AUTOSAR XML (schema 4-2-1)
package /RootP_ASWC_A7C
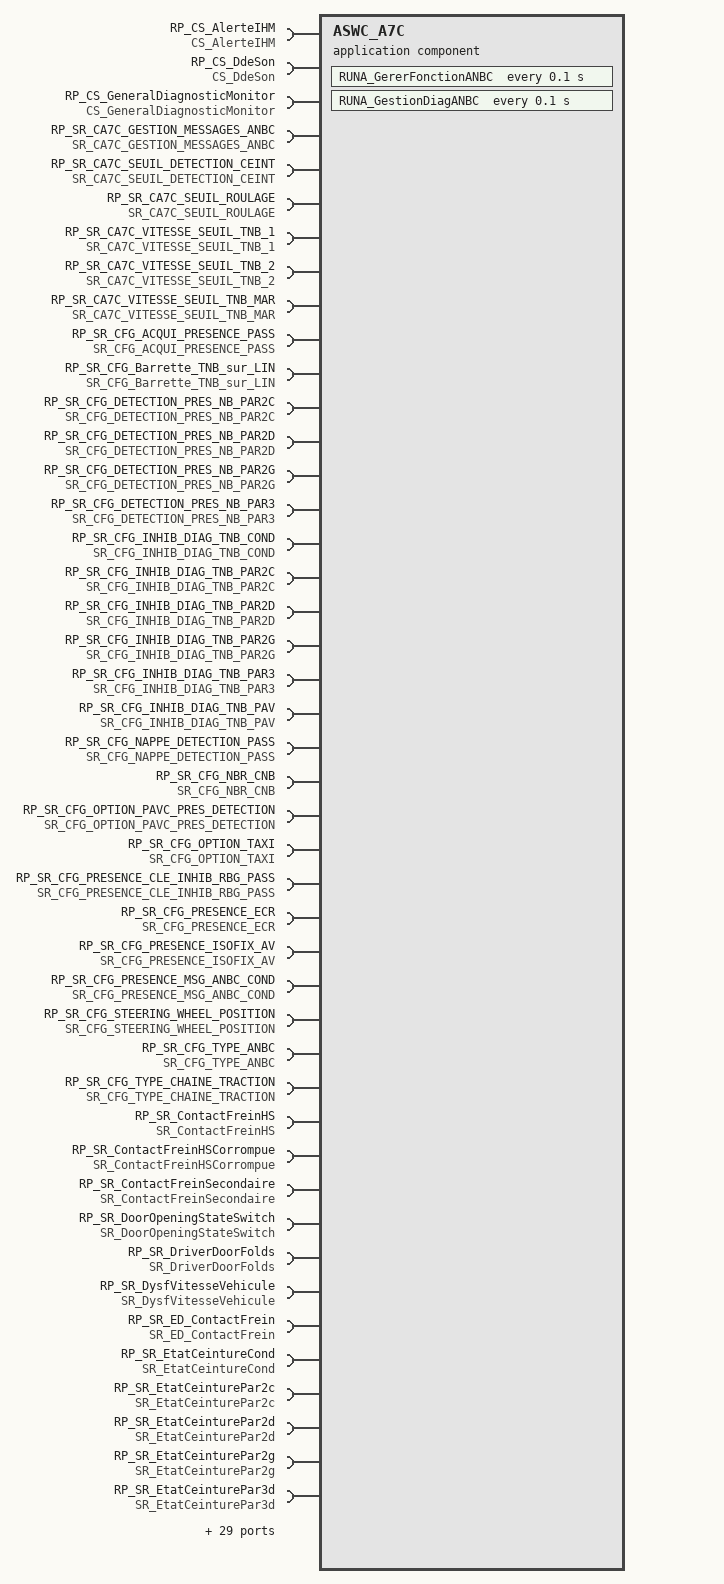
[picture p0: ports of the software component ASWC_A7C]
  application sw component type ASWC_A7C
    32 x provide/require port:
      PRP_SR_BMFPresente: nonqueued-receiver-com-spec{data-element=BMFPresente, enable-update=0, handle-data-status=1, handle-never-received=0, init-value=CONST_tLOG_0:0}, provided-required-interface=SR_BMFPresente
      PRP_SR_DdeClignoTemCeintAR2D: nonqueued-receiver-com-spec{data-element=DdeClignoTemCeintAR2D, enable-update=0, handle-data-status=1, handle-never-received=0, init-value=CONST_tLOG_0:0}, provided-required-interface=SR_DdeClignoTemCeintAR2D
      PRP_SR_DdeClignoTemCeintAR2G: nonqueued-receiver-com-spec{data-element=DdeClignoTemCeintAR2G, enable-update=0, handle-data-status=1, handle-never-received=0, init-value=CONST_tLOG_0:0}, provided-required-interface=SR_DdeClignoTemCeintAR2G
      PRP_SR_DdeClignoTemCeintAR2M: nonqueued-receiver-com-spec{data-element=DdeClignoTemCeintAR2M, enable-update=0, handle-data-status=1, handle-never-received=0, init-value=CONST_tLOG_0:0}, provided-required-interface=SR_DdeClignoTemCeintAR2M
      PRP_SR_DdeClignoTemCeintAR3D: nonqueued-receiver-com-spec{data-element=DdeClignoTemCeintAR3D, enable-update=0, handle-data-status=1, handle-never-received=0, init-value=CONST_tLOG_0:0}, provided-required-interface=SR_DdeClignoTemCeintAR3D
      PRP_SR_DdeClignoTemCeintAR3G: nonqueued-receiver-com-spec{data-element=DdeClignoTemCeintAR3G, enable-update=0, handle-data-status=1, handle-never-received=0, init-value=CONST_tLOG_0:0}, provided-required-interface=SR_DdeClignoTemCeintAR3G
      PRP_SR_DdeClignoTemCeintCond: nonqueued-receiver-com-spec{data-element=DdeClignoTemCeintCond, enable-update=0, handle-data-status=1, handle-never-received=0, init-value=CONST_tLOG_0:0}, provided-required-interface=SR_DdeClignoTemCeintCond
      PRP_SR_DdeClignoTemCeintPav: nonqueued-receiver-com-spec{data-element=DdeClignoTemCeintPav, enable-update=0, handle-data-status=1, handle-never-received=0, init-value=CONST_tLOG_0:0}, provided-required-interface=SR_DdeClignoTemCeintPav
      PRP_SR_DdeClignoTemCeintPavC: nonqueued-receiver-com-spec{data-element=DdeClignoTemCeintPavC, enable-update=0, handle-data-status=1, handle-never-received=0, init-value=CONST_tLOG_0:0}, provided-required-interface=SR_DdeClignoTemCeintPavC
      PRP_SR_DdeTemoinCeintureAR2D: nonqueued-receiver-com-spec{data-element=DdeTemoinCeintureAR2D, enable-update=0, handle-data-status=1, handle-never-received=0, init-value=CONST_tLOG_0:0}, provided-required-interface=SR_DdeTemoinCeintureAR2D
      PRP_SR_DdeTemoinCeintureAR2G: nonqueued-receiver-com-spec{data-element=DdeTemoinCeintureAR2G, enable-update=0, handle-data-status=1, handle-never-received=0, init-value=CONST_tLOG_0:0}, provided-required-interface=SR_DdeTemoinCeintureAR2G
      PRP_SR_DdeTemoinCeintureAR2M: nonqueued-receiver-com-spec{data-element=DdeTemoinCeintureAR2M, enable-update=0, handle-data-status=1, handle-never-received=0, init-value=CONST_tLOG_0:0}, provided-required-interface=SR_DdeTemoinCeintureAR2M
      PRP_SR_DdeTemoinCeintureAR3D: nonqueued-receiver-com-spec{data-element=DdeTemoinCeintureAR3D, enable-update=0, handle-data-status=1, handle-never-received=0, init-value=CONST_tLOG_0:0}, provided-required-interface=SR_DdeTemoinCeintureAR3D
      PRP_SR_DdeTemoinCeintureAR3G: nonqueued-receiver-com-spec{data-element=DdeTemoinCeintureAR3G, enable-update=0, handle-data-status=1, handle-never-received=0, init-value=CONST_tLOG_0:0}, provided-required-interface=SR_DdeTemoinCeintureAR3G
      PRP_SR_DdeTemoinCeintureCond: nonqueued-receiver-com-spec{data-element=DdeTemoinCeintureCond, enable-update=0, handle-data-status=1, handle-never-received=0, init-value=CONST_tLOG_0:0}, provided-required-interface=SR_DdeTemoinCeintureCond
      PRP_SR_DdeTemoinCeinturePav: nonqueued-receiver-com-spec{data-element=DdeTemoinCeinturePav, enable-update=0, handle-data-status=1, handle-never-received=0, init-value=CONST_tLOG_0:0}, provided-required-interface=SR_DdeTemoinCeinturePav
      PRP_SR_DdeTemoinCeinturePavC: nonqueued-receiver-com-spec{data-element=DdeTemoinCeinturePavC, enable-update=0, handle-data-status=1, handle-never-received=0, init-value=CONST_tLOG_0:0}, provided-required-interface=SR_DdeTemoinCeinturePavC
      PRP_SR_DiagDefautPresenceConducteur: nonqueued-receiver-com-spec{data-element=DiagDefautPresenceConducteur, enable-update=0, handle-data-status=1, handle-never-received=0, init-value=CONST_DiagDefautPresenceConducteur_t_cDefautPresConducteur_cDefautPresConducteur_Ok:0}, provided-required-interface=SR_DiagDefautPresenceConducteur
      PRP_SR_EtatBouclageDiff: nonqueued-receiver-com-spec{data-element=EtatBouclageDiff, enable-update=0, handle-data-status=1, handle-never-received=0, init-value=CONST_t_cBouclage_0:0}, provided-required-interface=SR_EtatBouclageDiff
      PRP_SR_PresenceConducteurDiag: nonqueued-receiver-com-spec{data-element=PresenceConducteurDiag, enable-update=0, handle-data-status=1, handle-never-received=0, init-value=CONST_tLOG_0:0}, provided-required-interface=SR_PresenceConducteurDiag
      PRP_SR_PresenceConducteurMux: nonqueued-receiver-com-spec{data-element=PresenceConducteurMux, enable-update=0, handle-data-status=1, handle-never-received=0, init-value=CONST_PresenceConducteurMux_t_cPresenceConducteur_cPresenceConducteur_Absent:1}, provided-required-interface=SR_PresenceConducteurMux
      PRP_SR_PresenceSimpleConducteur: nonqueued-receiver-com-spec{data-element=PresenceSimpleConducteur, enable-update=0, handle-data-status=1, handle-never-received=0, init-value=CONST_PresenceSimpleConducteur_t_cPresenceSimpleConducteur_cPresenceSimpleConducteur_Absent:0}, provided-required-interface=SR_PresenceSimpleConducteur
      PRP_SR_SAV_EtatCNBMemorisePar2c: nonqueued-receiver-com-spec{data-element=SAV_EtatCNBMemorisePar2c, enable-update=0, handle-data-status=1, handle-never-received=0, init-value=CONST_tLOG_0:0}, provided-required-interface=SR_SAV_EtatCNBMemorisePar2c
      PRP_SR_SAV_EtatCNBMemorisePar2d: nonqueued-receiver-com-spec{data-element=SAV_EtatCNBMemorisePar2d, enable-update=0, handle-data-status=1, handle-never-received=0, init-value=CONST_tLOG_0:0}, provided-required-interface=SR_SAV_EtatCNBMemorisePar2d
      PRP_SR_SAV_EtatCNBMemorisePar2g: nonqueued-receiver-com-spec{data-element=SAV_EtatCNBMemorisePar2g, enable-update=0, handle-data-status=1, handle-never-received=0, init-value=CONST_tLOG_0:0}, provided-required-interface=SR_SAV_EtatCNBMemorisePar2g
      PRP_SR_SAV_EtatCNBMemorisePar3d: nonqueued-receiver-com-spec{data-element=SAV_EtatCNBMemorisePar3d, enable-update=0, handle-data-status=1, handle-never-received=0, init-value=CONST_tLOG_0:0}, provided-required-interface=SR_SAV_EtatCNBMemorisePar3d
      PRP_SR_SAV_EtatCNBMemorisePar3g: nonqueued-receiver-com-spec{data-element=SAV_EtatCNBMemorisePar3g, enable-update=0, handle-data-status=1, handle-never-received=0, init-value=CONST_tLOG_0:0}, provided-required-interface=SR_SAV_EtatCNBMemorisePar3g
      PRP_SR_SAV_EtatCNBMemorisePavC: nonqueued-receiver-com-spec{data-element=SAV_EtatCNBMemorisePavC, enable-update=0, handle-data-status=1, handle-never-received=0, init-value=CONST_tLOG_0:0}, provided-required-interface=SR_SAV_EtatCNBMemorisePavC
      PRP_SR_SAV_EtatCNBMemorisePavd: nonqueued-receiver-com-spec{data-element=SAV_EtatCNBMemorisePavd, enable-update=0, handle-data-status=1, handle-never-received=0, init-value=CONST_tLOG_0:0}, provided-required-interface=SR_SAV_EtatCNBMemorisePavd
      PRP_SR_SAV_EtatCNBMemorisePavg: nonqueued-receiver-com-spec{data-element=SAV_EtatCNBMemorisePavg, enable-update=0, handle-data-status=1, handle-never-received=0, init-value=CONST_tLOG_0:0}, provided-required-interface=SR_SAV_EtatCNBMemorisePavg
      PRP_SR_SAV_EtatPresenceMemorisePav: nonqueued-receiver-com-spec{data-element=SAV_EtatPresenceMemorisePav, enable-update=0, handle-data-status=1, handle-never-received=0, init-value=CONST_tLOG_0:0}, provided-required-interface=SR_SAV_EtatPresenceMemorisePav
      PRP_SR_TypeSonANBC: nonqueued-receiver-com-spec{data-element=TypeSonANBC, enable-update=0, handle-data-status=1, handle-never-received=0, init-value=CONST_t_cTypeSonANBC_0:0}, provided-required-interface=SR_TypeSonANBC
    73 x require port:
      RP_CS_AlerteIHM: required-interface=CS_AlerteIHM
      RP_CS_DdeSon: required-interface=CS_DdeSon
      RP_CS_GeneralDiagnosticMonitor: required-interface=CS_GeneralDiagnosticMonitor
      RP_SR_CA7C_GESTION_MESSAGES_ANBC: nonqueued-receiver-com-spec{data-element=CA7C_GESTION_MESSAGES_ANBC, enable-update=0, handle-data-status=1, handle-never-received=0, init-value=CONST_tLOG_1:1}, required-interface=SR_CA7C_GESTION_MESSAGES_ANBC
      RP_SR_CA7C_SEUIL_DETECTION_CEINT: nonqueued-receiver-com-spec{data-element=CA7C_SEUIL_DETECTION_CEINT, enable-update=0, handle-data-status=1, handle-never-received=0, init-value=CONST_tBYTE_20:20}, required-interface=SR_CA7C_SEUIL_DETECTION_CEINT
      RP_SR_CA7C_SEUIL_ROULAGE: nonqueued-receiver-com-spec{data-element=CA7C_SEUIL_ROULAGE, enable-update=0, handle-data-status=1, handle-never-received=0, init-value=CONST_tBYTE_3:3}, required-interface=SR_CA7C_SEUIL_ROULAGE
      RP_SR_CA7C_VITESSE_SEUIL_TNB_1: nonqueued-receiver-com-spec{data-element=CA7C_VITESSE_SEUIL_TNB_1, enable-update=0, handle-data-status=1, handle-never-received=0, init-value=CONST_tBYTE_20:20}, required-interface=SR_CA7C_VITESSE_SEUIL_TNB_1
      RP_SR_CA7C_VITESSE_SEUIL_TNB_2: nonqueued-receiver-com-spec{data-element=CA7C_VITESSE_SEUIL_TNB_2, enable-update=0, handle-data-status=1, handle-never-received=0, init-value=CONST_tBYTE_20:20}, required-interface=SR_CA7C_VITESSE_SEUIL_TNB_2
      RP_SR_CA7C_VITESSE_SEUIL_TNB_MAR: nonqueued-receiver-com-spec{data-element=CA7C_VITESSE_SEUIL_TNB_MAR, enable-update=0, handle-data-status=1, handle-never-received=0, init-value=CONST_tBYTE_10:10}, required-interface=SR_CA7C_VITESSE_SEUIL_TNB_MAR
      RP_SR_CFG_ACQUI_PRESENCE_PASS: nonqueued-receiver-com-spec{data-element=CFG_ACQUI_PRESENCE_PASS, enable-update=0, handle-data-status=1, handle-never-received=0, init-value=CONST_tLOG_0:0}, required-interface=SR_CFG_ACQUI_PRESENCE_PASS
      RP_SR_CFG_Barrette_TNB_sur_LIN: nonqueued-receiver-com-spec{data-element=CFG_Barrette_TNB_sur_LIN, enable-update=0, handle-data-status=1, handle-never-received=0, init-value=CONST_tLOG_0:0}, required-interface=SR_CFG_Barrette_TNB_sur_LIN
      RP_SR_CFG_DETECTION_PRES_NB_PAR2C: nonqueued-receiver-com-spec{data-element=CFG_DETECTION_PRES_NB_PAR2C, enable-update=0, handle-data-status=1, handle-never-received=0, init-value=CONST_tLOG_0:0}, required-interface=SR_CFG_DETECTION_PRES_NB_PAR2C
      RP_SR_CFG_DETECTION_PRES_NB_PAR2D: nonqueued-receiver-com-spec{data-element=CFG_DETECTION_PRES_NB_PAR2D, enable-update=0, handle-data-status=1, handle-never-received=0, init-value=CONST_tLOG_0:0}, required-interface=SR_CFG_DETECTION_PRES_NB_PAR2D
      RP_SR_CFG_DETECTION_PRES_NB_PAR2G: nonqueued-receiver-com-spec{data-element=CFG_DETECTION_PRES_NB_PAR2G, enable-update=0, handle-data-status=1, handle-never-received=0, init-value=CONST_tLOG_0:0}, required-interface=SR_CFG_DETECTION_PRES_NB_PAR2G
      RP_SR_CFG_DETECTION_PRES_NB_PAR3: nonqueued-receiver-com-spec{data-element=CFG_DETECTION_PRES_NB_PAR3, enable-update=0, handle-data-status=1, handle-never-received=0, init-value=CONST_tLOG_0:0}, required-interface=SR_CFG_DETECTION_PRES_NB_PAR3
      RP_SR_CFG_INHIB_DIAG_TNB_COND: nonqueued-receiver-com-spec{data-element=CFG_INHIB_DIAG_TNB_COND, enable-update=0, handle-data-status=1, handle-never-received=0, init-value=CONST_tLOG_0:0}, required-interface=SR_CFG_INHIB_DIAG_TNB_COND
      RP_SR_CFG_INHIB_DIAG_TNB_PAR2C: nonqueued-receiver-com-spec{data-element=CFG_INHIB_DIAG_TNB_PAR2C, enable-update=0, handle-data-status=1, handle-never-received=0, init-value=CONST_tLOG_0:0}, required-interface=SR_CFG_INHIB_DIAG_TNB_PAR2C
      RP_SR_CFG_INHIB_DIAG_TNB_PAR2D: nonqueued-receiver-com-spec{data-element=CFG_INHIB_DIAG_TNB_PAR2D, enable-update=0, handle-data-status=1, handle-never-received=0, init-value=CONST_tLOG_0:0}, required-interface=SR_CFG_INHIB_DIAG_TNB_PAR2D
      RP_SR_CFG_INHIB_DIAG_TNB_PAR2G: nonqueued-receiver-com-spec{data-element=CFG_INHIB_DIAG_TNB_PAR2G, enable-update=0, handle-data-status=1, handle-never-received=0, init-value=CONST_tLOG_0:0}, required-interface=SR_CFG_INHIB_DIAG_TNB_PAR2G
      RP_SR_CFG_INHIB_DIAG_TNB_PAR3: nonqueued-receiver-com-spec{data-element=CFG_INHIB_DIAG_TNB_PAR3, enable-update=0, handle-data-status=1, handle-never-received=0, init-value=CONST_tLOG_0:0}, required-interface=SR_CFG_INHIB_DIAG_TNB_PAR3
      RP_SR_CFG_INHIB_DIAG_TNB_PAV: nonqueued-receiver-com-spec{data-element=CFG_INHIB_DIAG_TNB_PAV, enable-update=0, handle-data-status=1, handle-never-received=0, init-value=CONST_tLOG_0:0}, required-interface=SR_CFG_INHIB_DIAG_TNB_PAV
      RP_SR_CFG_NAPPE_DETECTION_PASS: nonqueued-receiver-com-spec{data-element=CFG_NAPPE_DETECTION_PASS, enable-update=0, handle-data-status=1, handle-never-received=0, init-value=CONST_tLOG_0:0}, required-interface=SR_CFG_NAPPE_DETECTION_PASS
      RP_SR_CFG_NBR_CNB: nonqueued-receiver-com-spec{data-element=CFG_NBR_CNB, enable-update=0, handle-data-status=1, handle-never-received=0, init-value=CONST_t_CFG_NBR_CNB_0:0}, required-interface=SR_CFG_NBR_CNB
      RP_SR_CFG_OPTION_PAVC_PRES_DETECTION: nonqueued-receiver-com-spec{data-element=CFG_OPTION_PAVC_PRES_DETECTION, enable-update=0, handle-data-status=1, handle-never-received=0, init-value=CONST_tLOG_0:0}, required-interface=SR_CFG_OPTION_PAVC_PRES_DETECTION
      RP_SR_CFG_OPTION_TAXI: nonqueued-receiver-com-spec{data-element=CFG_OPTION_TAXI, enable-update=0, handle-data-status=1, handle-never-received=0, init-value=CONST_tLOG_0:0}, required-interface=SR_CFG_OPTION_TAXI
      RP_SR_CFG_PRESENCE_CLE_INHIB_RBG_PASS: nonqueued-receiver-com-spec{data-element=CFG_PRESENCE_CLE_INHIB_RBG_PASS, enable-update=0, handle-data-status=1, handle-never-received=0, init-value=CONST_tLOG_0:0}, required-interface=SR_CFG_PRESENCE_CLE_INHIB_RBG_PASS
      RP_SR_CFG_PRESENCE_ECR: nonqueued-receiver-com-spec{data-element=CFG_PRESENCE_ECR, enable-update=0, handle-data-status=1, handle-never-received=0, init-value=CONST_t_cECR_A_0:0}, required-interface=SR_CFG_PRESENCE_ECR
      RP_SR_CFG_PRESENCE_ISOFIX_AV: nonqueued-receiver-com-spec{data-element=CFG_PRESENCE_ISOFIX_AV, enable-update=0, handle-data-status=1, handle-never-received=0, init-value=CONST_tLOG_0:0}, required-interface=SR_CFG_PRESENCE_ISOFIX_AV
      RP_SR_CFG_PRESENCE_MSG_ANBC_COND: nonqueued-receiver-com-spec{data-element=CFG_PRESENCE_MSG_ANBC_COND, enable-update=0, handle-data-status=1, handle-never-received=0, init-value=CONST_tLOG_0:0}, required-interface=SR_CFG_PRESENCE_MSG_ANBC_COND
      RP_SR_CFG_STEERING_WHEEL_POSITION: nonqueued-receiver-com-spec{data-element=CFG_STEERING_WHEEL_POSITION, enable-update=0, handle-data-status=1, handle-never-received=0, init-value=CONST_CFG_STEERING_WHEEL_POSITION_t_SteeringWheelPosition_eSteeringWheelPosition_Invalid:0}, required-interface=SR_CFG_STEERING_WHEEL_POSITION
      RP_SR_CFG_TYPE_ANBC: nonqueued-receiver-com-spec{data-element=CFG_TYPE_ANBC, enable-update=0, handle-data-status=1, handle-never-received=0, init-value=CONST_tLOG_0:0}, required-interface=SR_CFG_TYPE_ANBC
      RP_SR_CFG_TYPE_CHAINE_TRACTION: nonqueued-receiver-com-spec{data-element=CFG_TYPE_CHAINE_TRACTION, enable-update=0, handle-data-status=1, handle-never-received=0, init-value=CONST_CFG_TYPE_CHAINE_TRACTION_t_cTCT_cTCT_MTH:0}, required-interface=SR_CFG_TYPE_CHAINE_TRACTION
      RP_SR_ContactFreinHS: nonqueued-receiver-com-spec{data-element=ContactFreinHS, enable-update=0, handle-data-status=1, handle-never-received=0, init-value=CONST_tLOG_0:0}, required-interface=SR_ContactFreinHS
      RP_SR_ContactFreinHSCorrompue: nonqueued-receiver-com-spec{data-element=ContactFreinHSCorrompue, enable-update=0, handle-data-status=1, handle-never-received=0, init-value=CONST_tLOG_0:0}, required-interface=SR_ContactFreinHSCorrompue
      RP_SR_ContactFreinSecondaire: nonqueued-receiver-com-spec{data-element=ContactFreinSecondaire, enable-update=0, handle-data-status=1, handle-never-received=0, init-value=CONST_t_cContactFrein_0:0}, required-interface=SR_ContactFreinSecondaire
      RP_SR_DoorOpeningStateSwitch: nonqueued-receiver-com-spec{data-element=DoorOpeningState, enable-update=0, handle-data-status=1, handle-never-received=0, init-value=CONST_DoorOpeningState_tOpeningPosition_eMVA_None:0}, required-interface=SR_DoorOpeningStateSwitch
      RP_SR_DriverDoorFolds: required-interface=SR_DriverDoorFolds
        required-com-specs:
          data-element=DriverOpeningStateFolds, enable-update=0, handle-data-status=1, handle-never-received=0, init-value=CONST_tLOG_0:0
          data-element=DriverOpeningStateFoldsStatus, enable-update=0, handle-data-status=1, handle-never-received=0, init-value=CONST_DriverOpeningStateFoldsStatus_t_DriverOpeningStateFoldsStatus_eMVA_NoDefect:0
      RP_SR_DysfVitesseVehicule: nonqueued-receiver-com-spec{data-element=DysfVitesseVehicule, enable-update=0, handle-data-status=1, handle-never-received=0, init-value=CONST_t_cVitv_0:0}, required-interface=SR_DysfVitesseVehicule
      RP_SR_ED_ContactFrein: nonqueued-receiver-com-spec{data-element=ED_ContactFrein, enable-update=0, handle-data-status=1, handle-never-received=0, init-value=CONST_tLOG_0:0}, required-interface=SR_ED_ContactFrein
      RP_SR_EtatCeintureCond: nonqueued-receiver-com-spec{data-element=EtatCeintureCond, enable-update=0, handle-data-status=1, handle-never-received=0, init-value=CONST_EtatCeintureCond_t_cTNB_cTNB_Invalide:3}, required-interface=SR_EtatCeintureCond
      RP_SR_EtatCeinturePar2c: nonqueued-receiver-com-spec{data-element=EtatCeinturePar2c, enable-update=0, handle-data-status=1, handle-never-received=0, init-value=CONST_EtatCeinturePar2c_t_cTNB_cTNB_Invalide:3}, required-interface=SR_EtatCeinturePar2c
      RP_SR_EtatCeinturePar2d: nonqueued-receiver-com-spec{data-element=EtatCeinturePar2d, enable-update=0, handle-data-status=1, handle-never-received=0, init-value=CONST_EtatCeinturePar2d_t_cTNB_cTNB_Invalide:3}, required-interface=SR_EtatCeinturePar2d
      RP_SR_EtatCeinturePar2g: nonqueued-receiver-com-spec{data-element=EtatCeinturePar2g, enable-update=0, handle-data-status=1, handle-never-received=0, init-value=CONST_EtatCeinturePar2g_t_cTNB_cTNB_Invalide:3}, required-interface=SR_EtatCeinturePar2g
      RP_SR_EtatCeinturePar3d: nonqueued-receiver-com-spec{data-element=EtatCeinturePar3d, enable-update=0, handle-data-status=1, handle-never-received=0, init-value=CONST_EtatCeinturePar3d_t_cTNB_cTNB_Invalide:3}, required-interface=SR_EtatCeinturePar3d
      RP_SR_EtatCeinturePar3g: nonqueued-receiver-com-spec{data-element=EtatCeinturePar3g, enable-update=0, handle-data-status=1, handle-never-received=0, init-value=CONST_EtatCeinturePar3g_t_cTNB_cTNB_Invalide:3}, required-interface=SR_EtatCeinturePar3g
      RP_SR_EtatCeinturePav: nonqueued-receiver-com-spec{data-element=EtatCeinturePav, enable-update=0, handle-data-status=1, handle-never-received=0, init-value=CONST_EtatCeinturePav_t_cTNB_cTNB_Invalide:3}, required-interface=SR_EtatCeinturePav
      RP_SR_EtatCeinturePavC: nonqueued-receiver-com-spec{data-element=EtatCeinturePavC, enable-update=0, handle-data-status=1, handle-never-received=0, init-value=CONST_EtatCeinturePavC_t_cTNB_cTNB_Invalide:3}, required-interface=SR_EtatCeinturePavC
      RP_SR_EtatClefInhibRBAGPassager: nonqueued-receiver-com-spec{data-element=EtatClefInhibRBAGPassager, enable-update=0, handle-data-status=1, handle-never-received=0, init-value=CONST_t_cInhibRBGPass_0:0}, required-interface=SR_EtatClefInhibRBAGPassager
      RP_SR_EtatGMP: nonqueued-receiver-com-spec{data-element=EtatGMP, enable-update=0, handle-data-status=1, handle-never-received=0, init-value=CONST_EtatGMP_t_GM_GMP_GM_GMPCoupe:1}, required-interface=SR_EtatGMP
      RP_SR_EtatPrincipalSEV: nonqueued-receiver-com-spec{data-element=EtatPrincipalSEV, enable-update=0, handle-data-status=1, handle-never-received=0, init-value=CONST_EtatPrincipalSEV_t_SEV_SEV_Arret:105}, required-interface=SR_EtatPrincipalSEV
      RP_SR_InfoCpoCondRepli: nonqueued-receiver-com-spec{data-element=InfoCpoCondRepli, enable-update=0, handle-data-status=1, handle-never-received=0, init-value=CONST_tLOG_0:0}, required-interface=SR_InfoCpoCondRepli
      RP_SR_InterMemoDefauts: nonqueued-receiver-com-spec{data-element=InterMemoDefauts, enable-update=0, handle-data-status=1, handle-never-received=0, init-value=CONST_tLOG_0:0}, required-interface=SR_InterMemoDefauts
      RP_SR_MarcheArriere: nonqueued-receiver-com-spec{data-element=MarcheArriere, enable-update=0, handle-data-status=1, handle-never-received=0, init-value=CONST_tLOG_0:0}, required-interface=SR_MarcheArriere
      RP_SR_PhaseVieLS: nonqueued-receiver-com-spec{data-element=PhaseVieLS, enable-update=0, handle-data-status=1, handle-never-received=0, init-value=CONST_t_cCANLS_0:0}, required-interface=SR_PhaseVieLS
      RP_SR_PresencePassagerAvant: nonqueued-receiver-com-spec{data-element=PresencePassagerAvant, enable-update=0, handle-data-status=1, handle-never-received=0, init-value=CONST_tLOG_0:0}, required-interface=SR_PresencePassagerAvant
      RP_SR_SAV_CondaRealisee: nonqueued-receiver-com-spec{data-element=SAV_CondaRealisee, enable-update=0, handle-data-status=1, handle-never-received=0, init-value=CONST_SAV_CondaRealisee_t_cCR_cCR_Decondamne:1}, required-interface=SR_SAV_CondaRealisee
      RP_SR_SAV_EtatOuvrants: nonqueued-receiver-com-spec{data-element=SAV_EtatOuvrants, enable-update=0, handle-data-status=1, handle-never-received=0, init-value=CONST_t_cmEO_0:0}, required-interface=SR_SAV_EtatOuvrants
      RP_SR_SEC_ConfigSEV: nonqueued-receiver-com-spec{data-element=SEC_ConfigSEV, enable-update=0, handle-data-status=1, handle-never-received=0, init-value=CONST_t_cCSEV_4:4}, required-interface=SR_SEC_ConfigSEV
      RP_SR_TA7C_BOUCLAGE_CEINT_COND: nonqueued-receiver-com-spec{data-element=TA7C_BOUCLAGE_CEINT_COND, enable-update=0, handle-data-status=1, handle-never-received=0, init-value=CONST_t_TA7C_BOUCLAGE_CEINT_COND_60:60}, required-interface=SR_TA7C_BOUCLAGE_CEINT_COND
      RP_SR_TA7C_CONFIRM_DEBOUCLAGE_CEINT: nonqueued-receiver-com-spec{data-element=TA7C_CONFIRM_DEBOUCLAGE_CEINT, enable-update=0, handle-data-status=1, handle-never-received=0, init-value=CONST_tBYTE_1:1}, required-interface=SR_TA7C_CONFIRM_DEBOUCLAGE_CEINT
      RP_SR_TA7C_CONFIRM_OUVERTURE_PORTE: nonqueued-receiver-com-spec{data-element=TA7C_CONFIRM_OUVERTURE_PORTE, enable-update=0, handle-data-status=1, handle-never-received=0, init-value=CONST_tBYTE_1:1}, required-interface=SR_TA7C_CONFIRM_OUVERTURE_PORTE
      RP_SR_TA7C_DUREE_FORCAGE_TEMOINS_ARR: nonqueued-receiver-com-spec{data-element=TA7C_DUREE_FORCAGE_TEMOINS_ARR, enable-update=0, handle-data-status=1, handle-never-received=0, init-value=CONST_tBYTE_30:30}, required-interface=SR_TA7C_DUREE_FORCAGE_TEMOINS_ARR
      RP_SR_TA7C_FORCAGE_MAX_TNB: nonqueued-receiver-com-spec{data-element=TA7C_FORCAGE_MAX_TNB, enable-update=0, handle-data-status=1, handle-never-received=0, init-value=CONST_tBYTE_30:30}, required-interface=SR_TA7C_FORCAGE_MAX_TNB
      RP_SR_T_DUREE_SON_ANBC_NIV1: nonqueued-receiver-com-spec{data-element=T_DUREE_SON_ANBC_NIV1, enable-update=0, handle-data-status=1, handle-never-received=0, init-value=CONST_tBYTE_15:15}, required-interface=SR_T_DUREE_SON_ANBC_NIV1
      RP_SR_T_DUREE_SON_ANBC_NIV1_PRIM: nonqueued-receiver-com-spec{data-element=T_DUREE_SON_ANBC_NIV1_PRIM, enable-update=0, handle-data-status=1, handle-never-received=0, init-value=CONST_tBYTE_0:0}, required-interface=SR_T_DUREE_SON_ANBC_NIV1_PRIM
      RP_SR_T_DUREE_SON_ANBC_NIV2: nonqueued-receiver-com-spec{data-element=T_DUREE_SON_ANBC_NIV2, enable-update=0, handle-data-status=1, handle-never-received=0, init-value=CONST_tBYTE_15:15}, required-interface=SR_T_DUREE_SON_ANBC_NIV2
      RP_SR_T_DUREE_SON_ANBC_NIV2_PRIM: nonqueued-receiver-com-spec{data-element=T_DUREE_SON_ANBC_NIV2_PRIM, enable-update=0, handle-data-status=1, handle-never-received=0, init-value=CONST_tBYTE_0:0}, required-interface=SR_T_DUREE_SON_ANBC_NIV2_PRIM
      RP_SR_T_DUREE_SON_ANBC_NIV3: nonqueued-receiver-com-spec{data-element=T_DUREE_SON_ANBC_NIV3, enable-update=0, handle-data-status=1, handle-never-received=0, init-value=CONST_tBYTE_90:90}, required-interface=SR_T_DUREE_SON_ANBC_NIV3
      RP_SR_T_DUREE_SON_ANBC_NIV3_PRIM: nonqueued-receiver-com-spec{data-element=T_DUREE_SON_ANBC_NIV3_PRIM, enable-update=0, handle-data-status=1, handle-never-received=0, init-value=CONST_tBYTE_90:90}, required-interface=SR_T_DUREE_SON_ANBC_NIV3_PRIM
      RP_SR_TP7C_FILTRAGE_ABSENCE: nonqueued-receiver-com-spec{data-element=TP7C_FILTRAGE_ABSENCE, enable-update=0, handle-data-status=1, handle-never-received=0, init-value=CONST_t_TP7C_FILTRAGE_ABSENCE_0:0}, required-interface=SR_TP7C_FILTRAGE_ABSENCE
      RP_SR_VehicleLockingState: required-interface=SR_VehicleLockingState
        required-com-specs:
          data-element=VehicleLockingState, enable-update=0, handle-data-status=1, handle-never-received=0, init-value=CONST_tVehicleLockingState_0:0
          data-element=VehicleLockingStateMux, enable-update=0, handle-data-status=1, handle-never-received=0, init-value=CONST_VehicleLockingStateMux_tVehicleLockingStateMux_eMVA_InvalidMux:0
      RP_SR_VitesseVehicule: nonqueued-receiver-com-spec{data-element=VitesseVehicule, enable-update=0, handle-data-status=1, handle-never-received=0, init-value=CONST_tWORD_0:0}, required-interface=SR_VitesseVehicule
      ASWC_A7C_MSI: required-interface=AppModeInterface
    behavior IB_ASWC_A7C: data-type-mapping=ApplicationModeMapping, handle-termination-and-restart=NO-SUPPORT
      ar-typed-per-instance-memorys:
        122 x data:
          PA7C_AutorisationAlluForf: type=tLOG, init-value=CONST_tLOG_0:0
          PA7C_CauseDeLAlerte2c: type=tBYTE, init-value=CONST_tBYTE_0:0
          PA7C_CauseDeLAlerte2d: type=tBYTE, init-value=CONST_tBYTE_0:0
          PA7C_CauseDeLAlerte2g: type=tBYTE, init-value=CONST_tBYTE_0:0
          PA7C_CauseDeLAlerte3d: type=tBYTE, init-value=CONST_tBYTE_0:0
          PA7C_CauseDeLAlerte3g: type=tBYTE, init-value=CONST_tBYTE_0:0
          PA7C_CauseDeLAlerteCond: type=tBYTE, init-value=CONST_tBYTE_0:0
          PA7C_CauseDeLAlertePav: type=tBYTE, init-value=CONST_tBYTE_0:0
          PA7C_CauseDeLAlertePavC: type=tBYTE, init-value=CONST_tBYTE_0:0
          PA7C_CondaRealiseePrec: type=tBYTE, init-value=CONST_tBYTE_0x04:4
          PA7C_ConditionForcageTemoinsAR: type=tBYTE, init-value=CONST_tBYTE_0:0
          PA7C_CptTempoApp_DiagCNB: type=tWORD, init-value=CONST_tWORD_0:0
          PA7C_CptTempoApp_DiagCPO: type=tWORD, init-value=CONST_tWORD_0:0
          PA7C_CptTempoDisp_DiagCNB: type=tWORD, init-value=CONST_tWORD_0:0
          PA7C_CptTempoDisp_DiagCPO: type=tWORD, init-value=CONST_tWORD_0:0
          PA7C_DdeAlerteCeintAR2D: type=tLOG, init-value=CONST_tLOG_0:0
          PA7C_DdeAlerteCeintAR2G: type=tLOG, init-value=CONST_tLOG_0:0
          PA7C_DdeAlerteCeintAR2M: type=tLOG, init-value=CONST_tLOG_0:0
          PA7C_DdeAlerteCeintCond: type=tLOG, init-value=CONST_tLOG_0:0
          PA7C_DdeAlerteCeintPass: type=tLOG, init-value=CONST_tLOG_0:0
          PA7C_DdeAlerteCeintureAR2D: type=tLOG, init-value=CONST_tLOG_0:0
          PA7C_DdeAlerteCeintureAR2G: type=tLOG, init-value=CONST_tLOG_0:0
          PA7C_DdeAlerteCeintureAR2M: type=tLOG, init-value=CONST_tLOG_0:0
          PA7C_DdeAlerteCeintureCond: type=tLOG, init-value=CONST_tLOG_0:0
          PA7C_DdeAlerteCeinturePav: type=tLOG, init-value=CONST_tLOG_0:0
          PA7C_DdePresentationEtatCeintAR: type=tLOG, init-value=CONST_tLOG_0:0
          PA7C_DdePresEtatCeintAR: type=tLOG, init-value=CONST_tLOG_0:0
          PA7C_DdePresEtatCeintAR2C: type=tLOG, init-value=CONST_tLOG_0:0
          PA7C_DdePresEtatCeintAR2D: type=tLOG, init-value=CONST_tLOG_0:0
          PA7C_DdePresEtatCeintAR2G: type=tLOG, init-value=CONST_tLOG_0:0
          PA7C_DefautPrec_CNB: type=tBYTE, init-value=CONST_tBYTE_0:0
          PA7C_DefautPrec_CPO: type=tBYTE, init-value=CONST_tBYTE_0:0
          PA7C_ED_PresencePavPrec: type=tLOG, init-value=CONST_tLOG_1:1
          PA7C_EtatCeintCondPrec: type=tBILOG, init-value=CONST_tBILOG_1:1
          PA7C_EtatCeintPar2cPrec: type=tBILOG, init-value=CONST_tBILOG_1:1
          PA7C_EtatCeintPar2dPrec: type=tBILOG, init-value=CONST_tBILOG_1:1
          PA7C_EtatCeintPar2gPrec: type=tBILOG, init-value=CONST_tBILOG_1:1
          PA7C_EtatCeintPar3dPrec: type=tBILOG, init-value=CONST_tBILOG_1:1
          PA7C_EtatCeintPar3gPrec: type=tBILOG, init-value=CONST_tBILOG_1:1
          PA7C_EtatCeintPavCPrec: type=tBILOG, init-value=CONST_tBILOG_0:0
          PA7C_EtatCeintPavPrec: type=tBILOG, init-value=CONST_tBILOG_1:1
          PA7C_EtatCeintureCondPrec: type=tBILOG, init-value=CONST_tBILOG_0:0
          PA7C_EtatCeinturePavPrec: type=tBILOG, init-value=CONST_tBILOG_0:0
          PA7C_EtatFonctionTNB: type=tBYTE, init-value=CONST_tBYTE_0:0
          PA7C_EtatFonctionTNBPrec: type=tBYTE, init-value=CONST_tBYTE_0:0
          PA7C_EtatGMPPrec: type=tBYTE, init-value=CONST_tBYTE_0:0
          PA7C_EtatPortesPrec: type=tBYTE, init-value=CONST_tBYTE_0:0
          PA7C_EtatPrincipalSEVPrec: type=tBYTE, init-value=CONST_tBYTE_0:0
          PA7C_EtatRBGPrec: type=tBILOG, init-value=CONST_tBILOG_0:0
          PA7C_EtatsPrecValides: type=tLOG, init-value=CONST_tLOG_0:0
          PA7C_FlagInhibitionTNBParr2c: type=tLOG, init-value=CONST_tLOG_0:0
          PA7C_FlagInhibitionTNBParr2d: type=tLOG, init-value=CONST_tLOG_0:0
          PA7C_FlagInhibitionTNBParr2g: type=tLOG, init-value=CONST_tLOG_0:0
          PA7C_ForcerAlerteEnPostNiv2: type=tLOG, init-value=CONST_tLOG_0:0
          PA7C_GestionResetBSI: type=tLOG, init-value=CONST_tLOG_0:0
          PA7C_MarcheArrierePrec: type=tLOG, init-value=CONST_tLOG_0:0
          PA7C_NbBouclCondNonDetecte: type=tBYTE, init-value=CONST_tBYTE_0:0
          PA7C_NbrDePassagersDeboucles: type=tBYTE, init-value=CONST_tBYTE_0:0
          PA7C_NiveauAlerte2c: type=tBYTE, init-value=CONST_tBYTE_0:0
          PA7C_NiveauAlerte2d: type=tBYTE, init-value=CONST_tBYTE_0:0
          PA7C_NiveauAlerte2g: type=tBYTE, init-value=CONST_tBYTE_0:0
          PA7C_NiveauAlerte3d: type=tBYTE, init-value=CONST_tBYTE_0:0
          PA7C_NiveauAlerte3g: type=tBYTE, init-value=CONST_tBYTE_0:0
          PA7C_NiveauAlerteCond: type=tBYTE, init-value=CONST_tBYTE_0:0
          PA7C_NiveauAlertePav: type=tBYTE, init-value=CONST_tBYTE_0:0
          PA7C_NiveauAlertePavC: type=tBYTE, init-value=CONST_tBYTE_0:0
          PA7C_NiveauAlerteSon: type=tBILOG, init-value=CONST_tBILOG_0:0
          PA7C_OldStateDef2_DiagCNB: type=tBYTE, init-value=CONST_tBYTE_0:0
          PA7C_OldStateDef2_DiagCPO: type=tBYTE, init-value=CONST_tBYTE_0:0
          PA7C_PhaseVieLSPrec_DiagCNB: type=tBYTE, init-value=CONST_tBYTE_0:0
          PA7C_PhaseVieLSPrec_DiagCPO: type=tBYTE, init-value=CONST_tBYTE_0:0
          PA7C_PresAlerteCeintAR2D: type=tLOG, init-value=CONST_tLOG_0:0
          PA7C_PresAlerteCeintAR2G: type=tLOG, init-value=CONST_tLOG_0:0
          PA7C_PresAlerteCeintAR2M: type=tLOG, init-value=CONST_tLOG_0:0
          PA7C_PresAlerteCeintCond: type=tLOG, init-value=CONST_tLOG_0:0
          PA7C_PresAlerteCeintPass: type=tLOG, init-value=CONST_tLOG_0:0
          PA7C_PresMessEtatCeintAR2C: type=tLOG, init-value=CONST_tLOG_0:0
          PA7C_PresMessEtatCeintAR2D: type=tLOG, init-value=CONST_tLOG_0:0
          PA7C_PresMessEtatCeintAR2G: type=tLOG, init-value=CONST_tLOG_0:0
          PA7C_ResetBSI: type=tLOG, init-value=CONST_tLOG_0:0
          PA7C_ResetBSIaTraiter: type=tLOG, init-value=CONST_tLOG_0:0
          PA7C_ResetBSIDetecte: type=tLOG, init-value=CONST_tLOG_0:0
          PA7C_RtDdeRAZIndicDiagTNBPrec: type=tLOG, init-value=CONST_tLOG_0:0
          PA7C_SavNiveauAlerte2c: type=tBYTE, init-value=CONST_tBYTE_0xFF:255
          PA7C_SavNiveauAlerte2d: type=tBYTE, init-value=CONST_tBYTE_0xFF:255
          PA7C_SavNiveauAlerte2g: type=tBYTE, init-value=CONST_tBYTE_0xFF:255
          PA7C_SavNiveauAlerte3d: type=tBYTE, init-value=CONST_tBYTE_0xFF:255
          PA7C_SavNiveauAlerte3g: type=tBYTE, init-value=CONST_tBYTE_0xFF:255
          PA7C_SavNiveauAlerteCond: type=tBYTE, init-value=CONST_tBYTE_0xFF:255
          PA7C_SavNiveauAlertePav: type=tBYTE, init-value=CONST_tBYTE_0xFF:255
          PA7C_SavNiveauAlertePavC: type=tBYTE, init-value=CONST_tBYTE_0xFF:255
          PA7C_SPEED_EXCEEDED_THRESHOLD_NONBUCKLING: type=tLOG, init-value=CONST_tLOG_0:0
          PA7C_TempoAlerteSon: type=tWORD, init-value=CONST_tWORD_0:0
          PA7C_TempoBouclCeintCond: type=tWORD, init-value=CONST_tWORD_0x0000:0
          PA7C_TempoDebouclageCeint: type=tBYTE, init-value=CONST_tBYTE_0:0
          PA7C_TempoFiltrageAbsente: type=tBYTE, init-value=CONST_tBYTE_0xFF:255
          PA7C_TempoForcageTemoins: type=tWORD, init-value=CONST_tWORD_0:0
          PA7C_TempoForcageVoyantCond: type=tWORD, init-value=CONST_tWORD_0:0
          PA7C_TempoNiveau2c: type=tWORD, init-value=CONST_tWORD_0:0
          PA7C_TempoNiveau2d: type=tWORD, init-value=CONST_tWORD_0:0
          PA7C_TempoNiveau2g: type=tWORD, init-value=CONST_tWORD_0:0
          PA7C_TempoNiveau3d: type=tWORD, init-value=CONST_tWORD_0:0
          PA7C_TempoNiveau3g: type=tWORD, init-value=CONST_tWORD_0:0
          PA7C_TempoNiveauCond: type=tWORD, init-value=CONST_tWORD_0:0
          PA7C_TempoNiveauPav: type=tWORD, init-value=CONST_tWORD_0:0
          PA7C_TempoNiveauPavC: type=tWORD, init-value=CONST_tWORD_0:0
          PA7C_TempoOuvertureCond: type=tBYTE, init-value=CONST_tBYTE_0:0
          PA7C_TempoOuverturePav: type=tBYTE, init-value=CONST_tBYTE_0:0
          PA7C_TypeSonANBCAR2D: type=tLOG, init-value=CONST_tLOG_0:0
          PA7C_TypeSonANBCAR2G: type=tLOG, init-value=CONST_tLOG_0:0
          PA7C_TypeSonANBCAR2M: type=tLOG, init-value=CONST_tLOG_0:0
          PA7C_TypeSonANBCAR3D: type=tLOG, init-value=CONST_tLOG_0:0
          PA7C_TypeSonANBCAR3G: type=tLOG, init-value=CONST_tLOG_0:0
          PA7C_TypeSonANBCCond: type=tLOG, init-value=CONST_tLOG_0:0
          PA7C_TypeSonANBCPav: type=tLOG, init-value=CONST_tLOG_0:0
          PA7C_TypeSonANBCPavC: type=tLOG, init-value=CONST_tLOG_0:0
          PA7C_VitesseInfAuSeuilRoulage: type=tLOG, init-value=CONST_tLOG_0:0
          PA7C_VitesseInfAuSeuilTNB1: type=tLOG, init-value=CONST_tLOG_0:0
          PA7C_VitesseInfAuSeuilTNB1Prec: type=tLOG, init-value=CONST_tLOG_0:0
          PA7C_VitesseInfAuSeuilTNB2: type=tLOG, init-value=CONST_tLOG_0:0
          PA7C_VitesseInfAuSeuilTNB2Prec: type=tLOG, init-value=CONST_tLOG_0:0
          PA7C_VitesseInfRoulagePrec: type=tLOG, init-value=CONST_tLOG_1:1
      timing event RUNA_GererFonctionANBC_Cyclic: start-on-event=RUNA_GererFonctionANBC, period=0.1
        disabled-mode:
          ASWC_A7C_MSI.AppMode.APP_WAKEUP
          ASWC_A7C_MSI.AppMode.APP_OFF
          ASWC_A7C_MSI.AppMode.APP_SYNC_INIT
          ASWC_A7C_MSI.AppMode.APP_CONFIG
      timing event RUNA_GestionDiagANBC_Cyclic: start-on-event=RUNA_GestionDiagANBC, period=0.1
        disabled-mode:
          ASWC_A7C_MSI.AppMode.APP_WAKEUP
          ASWC_A7C_MSI.AppMode.APP_OFF
          ASWC_A7C_MSI.AppMode.APP_SYNC_INIT
          ASWC_A7C_MSI.AppMode.APP_CONFIG
      5 x runnable:
        RUNA_GererFonctionANBC
          data-read-access:
            100 x access:
              dra_RP_SR_ContactFreinHS_ContactFreinHS: accessed-variable=RP_SR_ContactFreinHS.ContactFreinHS
              dra_RP_SR_ContactFreinHSCorrompue_ContactFreinHSCorrompue: accessed-variable=RP_SR_ContactFreinHSCorrompue.ContactFreinHSCorrompue
              dra_RP_SR_ContactFreinSecondaire_ContactFreinSecondaire: accessed-variable=RP_SR_ContactFreinSecondaire.ContactFreinSecondaire
              dra_RP_SR_DoorOpeningStateSwitch_DoorOpeningState: accessed-variable=RP_SR_DoorOpeningStateSwitch.DoorOpeningState
              dra_RP_SR_DriverDoorFolds_DriverOpeningStateFolds: accessed-variable=RP_SR_DriverDoorFolds.DriverOpeningStateFolds
              dra_RP_SR_DriverDoorFolds_DriverOpeningStateFoldsStatus: accessed-variable=RP_SR_DriverDoorFolds.DriverOpeningStateFoldsStatus
              dra_RP_SR_DysfVitesseVehicule_DysfVitesseVehicule: accessed-variable=RP_SR_DysfVitesseVehicule.DysfVitesseVehicule
              dra_RP_SR_ED_ContactFrein_ED_ContactFrein: accessed-variable=RP_SR_ED_ContactFrein.ED_ContactFrein
              dra_RP_SR_EtatCeintureCond_EtatCeintureCond: accessed-variable=RP_SR_EtatCeintureCond.EtatCeintureCond
              dra_RP_SR_EtatCeinturePar2c_EtatCeinturePar2c: accessed-variable=RP_SR_EtatCeinturePar2c.EtatCeinturePar2c
              dra_RP_SR_EtatCeinturePar2d_EtatCeinturePar2d: accessed-variable=RP_SR_EtatCeinturePar2d.EtatCeinturePar2d
              dra_RP_SR_EtatCeinturePar2g_EtatCeinturePar2g: accessed-variable=RP_SR_EtatCeinturePar2g.EtatCeinturePar2g
              dra_RP_SR_EtatCeinturePar3d_EtatCeinturePar3d: accessed-variable=RP_SR_EtatCeinturePar3d.EtatCeinturePar3d
              dra_RP_SR_EtatCeinturePar3g_EtatCeinturePar3g: accessed-variable=RP_SR_EtatCeinturePar3g.EtatCeinturePar3g
              dra_RP_SR_EtatCeinturePav_EtatCeinturePav: accessed-variable=RP_SR_EtatCeinturePav.EtatCeinturePav
              dra_RP_SR_EtatCeinturePavC_EtatCeinturePavC: accessed-variable=RP_SR_EtatCeinturePavC.EtatCeinturePavC
              dra_RP_SR_EtatClefInhibRBAGPassager_EtatClefInhibRBAGPassager: accessed-variable=RP_SR_EtatClefInhibRBAGPassager.EtatClefInhibRBAGPassager
              dra_RP_SR_EtatGMP_EtatGMP: accessed-variable=RP_SR_EtatGMP.EtatGMP
              dra_RP_SR_EtatPrincipalSEV_EtatPrincipalSEV: accessed-variable=RP_SR_EtatPrincipalSEV.EtatPrincipalSEV
              dra_RP_SR_InfoCpoCondRepli_InfoCpoCondRepli: accessed-variable=RP_SR_InfoCpoCondRepli.InfoCpoCondRepli
              dra_RP_SR_MarcheArriere_MarcheArriere: accessed-variable=RP_SR_MarcheArriere.MarcheArriere
              dra_RP_SR_PresencePassagerAvant_PresencePassagerAvant: accessed-variable=RP_SR_PresencePassagerAvant.PresencePassagerAvant
              dra_RP_SR_SAV_CondaRealisee_SAV_CondaRealisee: accessed-variable=RP_SR_SAV_CondaRealisee.SAV_CondaRealisee
              dra_RP_SR_SAV_EtatOuvrants_SAV_EtatOuvrants: accessed-variable=RP_SR_SAV_EtatOuvrants.SAV_EtatOuvrants
              dra_RP_SR_SEC_ConfigSEV_SEC_ConfigSEV: accessed-variable=RP_SR_SEC_ConfigSEV.SEC_ConfigSEV
              dra_RP_SR_VehicleLockingState_VehicleLockingState: accessed-variable=RP_SR_VehicleLockingState.VehicleLockingState
              dra_RP_SR_VehicleLockingState_VehicleLockingStateMux: accessed-variable=RP_SR_VehicleLockingState.VehicleLockingStateMux
              dra_RP_SR_VitesseVehicule_VitesseVehicule: accessed-variable=RP_SR_VitesseVehicule.VitesseVehicule
              dra_RP_SR_CA7C_GESTION_MESSAGES_ANBC_CA7C_GESTION_MESSAGES_ANBC: accessed-variable=RP_SR_CA7C_GESTION_MESSAGES_ANBC.CA7C_GESTION_MESSAGES_ANBC
              dra_RP_SR_CA7C_SEUIL_DETECTION_CEINT_CA7C_SEUIL_DETECTION_CEINT: accessed-variable=RP_SR_CA7C_SEUIL_DETECTION_CEINT.CA7C_SEUIL_DETECTION_CEINT
              dra_RP_SR_CA7C_SEUIL_ROULAGE_CA7C_SEUIL_ROULAGE: accessed-variable=RP_SR_CA7C_SEUIL_ROULAGE.CA7C_SEUIL_ROULAGE
              dra_RP_SR_CA7C_VITESSE_SEUIL_TNB_1_CA7C_VITESSE_SEUIL_TNB_1: accessed-variable=RP_SR_CA7C_VITESSE_SEUIL_TNB_1.CA7C_VITESSE_SEUIL_TNB_1
              dra_RP_SR_CA7C_VITESSE_SEUIL_TNB_2_CA7C_VITESSE_SEUIL_TNB_2: accessed-variable=RP_SR_CA7C_VITESSE_SEUIL_TNB_2.CA7C_VITESSE_SEUIL_TNB_2
              dra_RP_SR_CA7C_VITESSE_SEUIL_TNB_MAR_CA7C_VITESSE_SEUIL_TNB_MAR: accessed-variable=RP_SR_CA7C_VITESSE_SEUIL_TNB_MAR.CA7C_VITESSE_SEUIL_TNB_MAR
              dra_RP_SR_CFG_ACQUI_PRESENCE_PASS_CFG_ACQUI_PRESENCE_PASS: accessed-variable=RP_SR_CFG_ACQUI_PRESENCE_PASS.CFG_ACQUI_PRESENCE_PASS
              dra_RP_SR_CFG_Barrette_TNB_sur_LIN_CFG_Barrette_TNB_sur_LIN: accessed-variable=RP_SR_CFG_Barrette_TNB_sur_LIN.CFG_Barrette_TNB_sur_LIN
              dra_RP_SR_CFG_DETECTION_PRES_NB_PAR2C_CFG_DETECTION_PRES_NB_PAR2C: accessed-variable=RP_SR_CFG_DETECTION_PRES_NB_PAR2C.CFG_DETECTION_PRES_NB_PAR2C
              dra_RP_SR_CFG_DETECTION_PRES_NB_PAR2D_CFG_DETECTION_PRES_NB_PAR2D: accessed-variable=RP_SR_CFG_DETECTION_PRES_NB_PAR2D.CFG_DETECTION_PRES_NB_PAR2D
              dra_RP_SR_CFG_DETECTION_PRES_NB_PAR2G_CFG_DETECTION_PRES_NB_PAR2G: accessed-variable=RP_SR_CFG_DETECTION_PRES_NB_PAR2G.CFG_DETECTION_PRES_NB_PAR2G
              dra_RP_SR_CFG_DETECTION_PRES_NB_PAR3_CFG_DETECTION_PRES_NB_PAR3: accessed-variable=RP_SR_CFG_DETECTION_PRES_NB_PAR3.CFG_DETECTION_PRES_NB_PAR3
              dra_RP_SR_CFG_INHIB_DIAG_TNB_COND_CFG_INHIB_DIAG_TNB_COND: accessed-variable=RP_SR_CFG_INHIB_DIAG_TNB_COND.CFG_INHIB_DIAG_TNB_COND
              dra_RP_SR_CFG_INHIB_DIAG_TNB_PAR2C_CFG_INHIB_DIAG_TNB_PAR2C: accessed-variable=RP_SR_CFG_INHIB_DIAG_TNB_PAR2C.CFG_INHIB_DIAG_TNB_PAR2C
              dra_RP_SR_CFG_INHIB_DIAG_TNB_PAR2D_CFG_INHIB_DIAG_TNB_PAR2D: accessed-variable=RP_SR_CFG_INHIB_DIAG_TNB_PAR2D.CFG_INHIB_DIAG_TNB_PAR2D
              dra_RP_SR_CFG_INHIB_DIAG_TNB_PAR2G_CFG_INHIB_DIAG_TNB_PAR2G: accessed-variable=RP_SR_CFG_INHIB_DIAG_TNB_PAR2G.CFG_INHIB_DIAG_TNB_PAR2G
              dra_RP_SR_CFG_INHIB_DIAG_TNB_PAR3_CFG_INHIB_DIAG_TNB_PAR3: accessed-variable=RP_SR_CFG_INHIB_DIAG_TNB_PAR3.CFG_INHIB_DIAG_TNB_PAR3
              dra_RP_SR_CFG_INHIB_DIAG_TNB_PAV_CFG_INHIB_DIAG_TNB_PAV: accessed-variable=RP_SR_CFG_INHIB_DIAG_TNB_PAV.CFG_INHIB_DIAG_TNB_PAV
              dra_RP_SR_CFG_NAPPE_DETECTION_PASS_CFG_NAPPE_DETECTION_PASS: accessed-variable=RP_SR_CFG_NAPPE_DETECTION_PASS.CFG_NAPPE_DETECTION_PASS
              dra_RP_SR_CFG_NBR_CNB_CFG_NBR_CNB: accessed-variable=RP_SR_CFG_NBR_CNB.CFG_NBR_CNB
              dra_RP_SR_CFG_OPTION_PAVC_PRES_DETECTION_CFG_OPTION_PAVC_PRES_DETECTION: accessed-variable=RP_SR_CFG_OPTION_PAVC_PRES_DETECTION.CFG_OPTION_PAVC_PRES_DETECTION
              dra_RP_SR_CFG_OPTION_TAXI_CFG_OPTION_TAXI: accessed-variable=RP_SR_CFG_OPTION_TAXI.CFG_OPTION_TAXI
              dra_RP_SR_CFG_PRESENCE_CLE_INHIB_RBG_PASS_CFG_PRESENCE_CLE_INHIB_RBG_PASS: accessed-variable=RP_SR_CFG_PRESENCE_CLE_INHIB_RBG_PASS.CFG_PRESENCE_CLE_INHIB_RBG_PASS
              dra_RP_SR_CFG_PRESENCE_ISOFIX_AV_CFG_PRESENCE_ISOFIX_AV: accessed-variable=RP_SR_CFG_PRESENCE_ISOFIX_AV.CFG_PRESENCE_ISOFIX_AV
              dra_RP_SR_CFG_PRESENCE_MSG_ANBC_COND_CFG_PRESENCE_MSG_ANBC_COND: accessed-variable=RP_SR_CFG_PRESENCE_MSG_ANBC_COND.CFG_PRESENCE_MSG_ANBC_COND
              dra_RP_SR_CFG_STEERING_WHEEL_POSITION_CFG_STEERING_WHEEL_POSITION: accessed-variable=RP_SR_CFG_STEERING_WHEEL_POSITION.CFG_STEERING_WHEEL_POSITION
              dra_RP_SR_CFG_TYPE_ANBC_CFG_TYPE_ANBC: accessed-variable=RP_SR_CFG_TYPE_ANBC.CFG_TYPE_ANBC
              dra_RP_SR_CFG_TYPE_CHAINE_TRACTION_CFG_TYPE_CHAINE_TRACTION: accessed-variable=RP_SR_CFG_TYPE_CHAINE_TRACTION.CFG_TYPE_CHAINE_TRACTION
              dra_RP_SR_TA7C_BOUCLAGE_CEINT_COND_TA7C_BOUCLAGE_CEINT_COND: accessed-variable=RP_SR_TA7C_BOUCLAGE_CEINT_COND.TA7C_BOUCLAGE_CEINT_COND
              dra_RP_SR_TA7C_CONFIRM_DEBOUCLAGE_CEINT_TA7C_CONFIRM_DEBOUCLAGE_CEINT: accessed-variable=RP_SR_TA7C_CONFIRM_DEBOUCLAGE_CEINT.TA7C_CONFIRM_DEBOUCLAGE_CEINT
              dra_RP_SR_TA7C_CONFIRM_OUVERTURE_PORTE_TA7C_CONFIRM_OUVERTURE_PORTE: accessed-variable=RP_SR_TA7C_CONFIRM_OUVERTURE_PORTE.TA7C_CONFIRM_OUVERTURE_PORTE
              dra_RP_SR_TA7C_DUREE_FORCAGE_TEMOINS_ARR_TA7C_DUREE_FORCAGE_TEMOINS_ARR: accessed-variable=RP_SR_TA7C_DUREE_FORCAGE_TEMOINS_ARR.TA7C_DUREE_FORCAGE_TEMOINS_ARR
              dra_RP_SR_TA7C_FORCAGE_MAX_TNB_TA7C_FORCAGE_MAX_TNB: accessed-variable=RP_SR_TA7C_FORCAGE_MAX_TNB.TA7C_FORCAGE_MAX_TNB
              dra_RP_SR_T_DUREE_SON_ANBC_NIV1_T_DUREE_SON_ANBC_NIV1: accessed-variable=RP_SR_T_DUREE_SON_ANBC_NIV1.T_DUREE_SON_ANBC_NIV1
              dra_RP_SR_T_DUREE_SON_ANBC_NIV1_PRIM_T_DUREE_SON_ANBC_NIV1_PRIM: accessed-variable=RP_SR_T_DUREE_SON_ANBC_NIV1_PRIM.T_DUREE_SON_ANBC_NIV1_PRIM
              dra_RP_SR_T_DUREE_SON_ANBC_NIV2_T_DUREE_SON_ANBC_NIV2: accessed-variable=RP_SR_T_DUREE_SON_ANBC_NIV2.T_DUREE_SON_ANBC_NIV2
              dra_RP_SR_T_DUREE_SON_ANBC_NIV2_PRIM_T_DUREE_SON_ANBC_NIV2_PRIM: accessed-variable=RP_SR_T_DUREE_SON_ANBC_NIV2_PRIM.T_DUREE_SON_ANBC_NIV2_PRIM
              dra_RP_SR_T_DUREE_SON_ANBC_NIV3_T_DUREE_SON_ANBC_NIV3: accessed-variable=RP_SR_T_DUREE_SON_ANBC_NIV3.T_DUREE_SON_ANBC_NIV3
              dra_RP_SR_T_DUREE_SON_ANBC_NIV3_PRIM_T_DUREE_SON_ANBC_NIV3_PRIM: accessed-variable=RP_SR_T_DUREE_SON_ANBC_NIV3_PRIM.T_DUREE_SON_ANBC_NIV3_PRIM
              dra_RP_SR_TP7C_FILTRAGE_ABSENCE_TP7C_FILTRAGE_ABSENCE: accessed-variable=RP_SR_TP7C_FILTRAGE_ABSENCE.TP7C_FILTRAGE_ABSENCE
              dra_PRP_SR_BMFPresente_BMFPresente: accessed-variable=PRP_SR_BMFPresente.BMFPresente
              dra_PRP_SR_DdeClignoTemCeintAR2D_DdeClignoTemCeintAR2D: accessed-variable=PRP_SR_DdeClignoTemCeintAR2D.DdeClignoTemCeintAR2D
              dra_PRP_SR_DdeClignoTemCeintAR2G_DdeClignoTemCeintAR2G: accessed-variable=PRP_SR_DdeClignoTemCeintAR2G.DdeClignoTemCeintAR2G
              dra_PRP_SR_DdeClignoTemCeintAR2M_DdeClignoTemCeintAR2M: accessed-variable=PRP_SR_DdeClignoTemCeintAR2M.DdeClignoTemCeintAR2M
              dra_PRP_SR_DdeClignoTemCeintAR3D_DdeClignoTemCeintAR3D: accessed-variable=PRP_SR_DdeClignoTemCeintAR3D.DdeClignoTemCeintAR3D
              dra_PRP_SR_DdeClignoTemCeintAR3G_DdeClignoTemCeintAR3G: accessed-variable=PRP_SR_DdeClignoTemCeintAR3G.DdeClignoTemCeintAR3G
              dra_PRP_SR_DdeClignoTemCeintCond_DdeClignoTemCeintCond: accessed-variable=PRP_SR_DdeClignoTemCeintCond.DdeClignoTemCeintCond
              dra_PRP_SR_DdeClignoTemCeintPav_DdeClignoTemCeintPav: accessed-variable=PRP_SR_DdeClignoTemCeintPav.DdeClignoTemCeintPav
              dra_PRP_SR_DdeClignoTemCeintPavC_DdeClignoTemCeintPavC: accessed-variable=PRP_SR_DdeClignoTemCeintPavC.DdeClignoTemCeintPavC
              dra_PRP_SR_DdeTemoinCeintureAR2D_DdeTemoinCeintureAR2D: accessed-variable=PRP_SR_DdeTemoinCeintureAR2D.DdeTemoinCeintureAR2D
              dra_PRP_SR_DdeTemoinCeintureAR2G_DdeTemoinCeintureAR2G: accessed-variable=PRP_SR_DdeTemoinCeintureAR2G.DdeTemoinCeintureAR2G
              dra_PRP_SR_DdeTemoinCeintureAR2M_DdeTemoinCeintureAR2M: accessed-variable=PRP_SR_DdeTemoinCeintureAR2M.DdeTemoinCeintureAR2M
              dra_PRP_SR_DdeTemoinCeintureAR3D_DdeTemoinCeintureAR3D: accessed-variable=PRP_SR_DdeTemoinCeintureAR3D.DdeTemoinCeintureAR3D
              dra_PRP_SR_DdeTemoinCeintureAR3G_DdeTemoinCeintureAR3G: accessed-variable=PRP_SR_DdeTemoinCeintureAR3G.DdeTemoinCeintureAR3G
              dra_PRP_SR_DdeTemoinCeintureCond_DdeTemoinCeintureCond: accessed-variable=PRP_SR_DdeTemoinCeintureCond.DdeTemoinCeintureCond
              dra_PRP_SR_DdeTemoinCeinturePav_DdeTemoinCeinturePav: accessed-variable=PRP_SR_DdeTemoinCeinturePav.DdeTemoinCeinturePav
              dra_PRP_SR_DdeTemoinCeinturePavC_DdeTemoinCeinturePavC: accessed-variable=PRP_SR_DdeTemoinCeinturePavC.DdeTemoinCeinturePavC
              dra_PRP_SR_DiagDefautPresenceConducteur_DiagDefautPresenceConducteur: accessed-variable=PRP_SR_DiagDefautPresenceConducteur.DiagDefautPresenceConducteur
              dra_PRP_SR_EtatBouclageDiff_EtatBouclageDiff: accessed-variable=PRP_SR_EtatBouclageDiff.EtatBouclageDiff
              dra_PRP_SR_PresenceConducteurDiag_PresenceConducteurDiag: accessed-variable=PRP_SR_PresenceConducteurDiag.PresenceConducteurDiag
              dra_PRP_SR_PresenceConducteurMux_PresenceConducteurMux: accessed-variable=PRP_SR_PresenceConducteurMux.PresenceConducteurMux
              dra_PRP_SR_PresenceSimpleConducteur_PresenceSimpleConducteur: accessed-variable=PRP_SR_PresenceSimpleConducteur.PresenceSimpleConducteur
              dra_PRP_SR_SAV_EtatCNBMemorisePar2c_SAV_EtatCNBMemorisePar2c: accessed-variable=PRP_SR_SAV_EtatCNBMemorisePar2c.SAV_EtatCNBMemorisePar2c
              dra_PRP_SR_SAV_EtatCNBMemorisePar2d_SAV_EtatCNBMemorisePar2d: accessed-variable=PRP_SR_SAV_EtatCNBMemorisePar2d.SAV_EtatCNBMemorisePar2d
              dra_PRP_SR_SAV_EtatCNBMemorisePar2g_SAV_EtatCNBMemorisePar2g: accessed-variable=PRP_SR_SAV_EtatCNBMemorisePar2g.SAV_EtatCNBMemorisePar2g
              dra_PRP_SR_SAV_EtatCNBMemorisePar3d_SAV_EtatCNBMemorisePar3d: accessed-variable=PRP_SR_SAV_EtatCNBMemorisePar3d.SAV_EtatCNBMemorisePar3d
              dra_PRP_SR_SAV_EtatCNBMemorisePar3g_SAV_EtatCNBMemorisePar3g: accessed-variable=PRP_SR_SAV_EtatCNBMemorisePar3g.SAV_EtatCNBMemorisePar3g
              dra_PRP_SR_SAV_EtatCNBMemorisePavC_SAV_EtatCNBMemorisePavC: accessed-variable=PRP_SR_SAV_EtatCNBMemorisePavC.SAV_EtatCNBMemorisePavC
              dra_PRP_SR_SAV_EtatCNBMemorisePavd_SAV_EtatCNBMemorisePavd: accessed-variable=PRP_SR_SAV_EtatCNBMemorisePavd.SAV_EtatCNBMemorisePavd
              dra_PRP_SR_SAV_EtatCNBMemorisePavg_SAV_EtatCNBMemorisePavg: accessed-variable=PRP_SR_SAV_EtatCNBMemorisePavg.SAV_EtatCNBMemorisePavg
              dra_PRP_SR_SAV_EtatPresenceMemorisePav_SAV_EtatPresenceMemorisePav: accessed-variable=PRP_SR_SAV_EtatPresenceMemorisePav.SAV_EtatPresenceMemorisePav
              dra_PRP_SR_TypeSonANBC_TypeSonANBC: accessed-variable=PRP_SR_TypeSonANBC.TypeSonANBC
          data-write-access:
            32 x access:
              dwa_PRP_SR_BMFPresente_BMFPresente: accessed-variable=PRP_SR_BMFPresente.BMFPresente
              dwa_PRP_SR_DdeClignoTemCeintAR2D_DdeClignoTemCeintAR2D: accessed-variable=PRP_SR_DdeClignoTemCeintAR2D.DdeClignoTemCeintAR2D
              dwa_PRP_SR_DdeClignoTemCeintAR2G_DdeClignoTemCeintAR2G: accessed-variable=PRP_SR_DdeClignoTemCeintAR2G.DdeClignoTemCeintAR2G
              dwa_PRP_SR_DdeClignoTemCeintAR2M_DdeClignoTemCeintAR2M: accessed-variable=PRP_SR_DdeClignoTemCeintAR2M.DdeClignoTemCeintAR2M
              dwa_PRP_SR_DdeClignoTemCeintAR3D_DdeClignoTemCeintAR3D: accessed-variable=PRP_SR_DdeClignoTemCeintAR3D.DdeClignoTemCeintAR3D
              dwa_PRP_SR_DdeClignoTemCeintAR3G_DdeClignoTemCeintAR3G: accessed-variable=PRP_SR_DdeClignoTemCeintAR3G.DdeClignoTemCeintAR3G
              dwa_PRP_SR_DdeClignoTemCeintCond_DdeClignoTemCeintCond: accessed-variable=PRP_SR_DdeClignoTemCeintCond.DdeClignoTemCeintCond
              dwa_PRP_SR_DdeClignoTemCeintPav_DdeClignoTemCeintPav: accessed-variable=PRP_SR_DdeClignoTemCeintPav.DdeClignoTemCeintPav
              dwa_PRP_SR_DdeClignoTemCeintPavC_DdeClignoTemCeintPavC: accessed-variable=PRP_SR_DdeClignoTemCeintPavC.DdeClignoTemCeintPavC
              dwa_PRP_SR_DdeTemoinCeintureAR2D_DdeTemoinCeintureAR2D: accessed-variable=PRP_SR_DdeTemoinCeintureAR2D.DdeTemoinCeintureAR2D
              dwa_PRP_SR_DdeTemoinCeintureAR2G_DdeTemoinCeintureAR2G: accessed-variable=PRP_SR_DdeTemoinCeintureAR2G.DdeTemoinCeintureAR2G
              dwa_PRP_SR_DdeTemoinCeintureAR2M_DdeTemoinCeintureAR2M: accessed-variable=PRP_SR_DdeTemoinCeintureAR2M.DdeTemoinCeintureAR2M
              dwa_PRP_SR_DdeTemoinCeintureAR3D_DdeTemoinCeintureAR3D: accessed-variable=PRP_SR_DdeTemoinCeintureAR3D.DdeTemoinCeintureAR3D
              dwa_PRP_SR_DdeTemoinCeintureAR3G_DdeTemoinCeintureAR3G: accessed-variable=PRP_SR_DdeTemoinCeintureAR3G.DdeTemoinCeintureAR3G
              dwa_PRP_SR_DdeTemoinCeintureCond_DdeTemoinCeintureCond: accessed-variable=PRP_SR_DdeTemoinCeintureCond.DdeTemoinCeintureCond
              dwa_PRP_SR_DdeTemoinCeinturePav_DdeTemoinCeinturePav: accessed-variable=PRP_SR_DdeTemoinCeinturePav.DdeTemoinCeinturePav
              dwa_PRP_SR_DdeTemoinCeinturePavC_DdeTemoinCeinturePavC: accessed-variable=PRP_SR_DdeTemoinCeinturePavC.DdeTemoinCeinturePavC
              dwa_PRP_SR_DiagDefautPresenceConducteur_DiagDefautPresenceConducteur: accessed-variable=PRP_SR_DiagDefautPresenceConducteur.DiagDefautPresenceConducteur
              dwa_PRP_SR_EtatBouclageDiff_EtatBouclageDiff: accessed-variable=PRP_SR_EtatBouclageDiff.EtatBouclageDiff
              dwa_PRP_SR_PresenceConducteurDiag_PresenceConducteurDiag: accessed-variable=PRP_SR_PresenceConducteurDiag.PresenceConducteurDiag
              dwa_PRP_SR_PresenceConducteurMux_PresenceConducteurMux: accessed-variable=PRP_SR_PresenceConducteurMux.PresenceConducteurMux
              dwa_PRP_SR_PresenceSimpleConducteur_PresenceSimpleConducteur: accessed-variable=PRP_SR_PresenceSimpleConducteur.PresenceSimpleConducteur
              dwa_PRP_SR_SAV_EtatCNBMemorisePar2c_SAV_EtatCNBMemorisePar2c: accessed-variable=PRP_SR_SAV_EtatCNBMemorisePar2c.SAV_EtatCNBMemorisePar2c
              dwa_PRP_SR_SAV_EtatCNBMemorisePar2d_SAV_EtatCNBMemorisePar2d: accessed-variable=PRP_SR_SAV_EtatCNBMemorisePar2d.SAV_EtatCNBMemorisePar2d
              dwa_PRP_SR_SAV_EtatCNBMemorisePar2g_SAV_EtatCNBMemorisePar2g: accessed-variable=PRP_SR_SAV_EtatCNBMemorisePar2g.SAV_EtatCNBMemorisePar2g
              dwa_PRP_SR_SAV_EtatCNBMemorisePar3d_SAV_EtatCNBMemorisePar3d: accessed-variable=PRP_SR_SAV_EtatCNBMemorisePar3d.SAV_EtatCNBMemorisePar3d
              dwa_PRP_SR_SAV_EtatCNBMemorisePar3g_SAV_EtatCNBMemorisePar3g: accessed-variable=PRP_SR_SAV_EtatCNBMemorisePar3g.SAV_EtatCNBMemorisePar3g
              dwa_PRP_SR_SAV_EtatCNBMemorisePavC_SAV_EtatCNBMemorisePavC: accessed-variable=PRP_SR_SAV_EtatCNBMemorisePavC.SAV_EtatCNBMemorisePavC
              dwa_PRP_SR_SAV_EtatCNBMemorisePavd_SAV_EtatCNBMemorisePavd: accessed-variable=PRP_SR_SAV_EtatCNBMemorisePavd.SAV_EtatCNBMemorisePavd
              dwa_PRP_SR_SAV_EtatCNBMemorisePavg_SAV_EtatCNBMemorisePavg: accessed-variable=PRP_SR_SAV_EtatCNBMemorisePavg.SAV_EtatCNBMemorisePavg
              dwa_PRP_SR_SAV_EtatPresenceMemorisePav_SAV_EtatPresenceMemorisePav: accessed-variable=PRP_SR_SAV_EtatPresenceMemorisePav.SAV_EtatPresenceMemorisePav
              dwa_PRP_SR_TypeSonANBC_TypeSonANBC: accessed-variable=PRP_SR_TypeSonANBC.TypeSonANBC
          sync call sscp_RUNA_GererFonctionANBC_CS_AlerteIHM_Cmd: operation=RP_CS_AlerteIHM.Cmd, timeout=0
          sync call sscp_RUNA_GererFonctionANBC_CS_DdeSon_Cmd: operation=RP_CS_DdeSon.Cmd, timeout=0
        RUNA_GestionDiagANBC
          data-read-access:
            4 x access:
              dra_PRP_SR_DiagDefautPresenceConducteur_DiagDefautPresenceConducteur: accessed-variable=PRP_SR_DiagDefautPresenceConducteur.DiagDefautPresenceConducteur
              dra_RP_SR_InterMemoDefauts_InterMemoDefauts: accessed-variable=RP_SR_InterMemoDefauts.InterMemoDefauts
              dra_RP_SR_PhaseVieLS_PhaseVieLS: accessed-variable=RP_SR_PhaseVieLS.PhaseVieLS
              dra_RP_SR_SEC_ConfigSEV_SEC_ConfigSEV: accessed-variable=RP_SR_SEC_ConfigSEV.SEC_ConfigSEV
          sync call sscp_RUNA_GestionDiagANBC_CS_GeneralDiagnosticMonitor_SetEventStatus: operation=RP_CS_GeneralDiagnosticMonitor.SetEventStatus, timeout=0
        RUNS_Routine_RAZIndicDiagTNB_RequestResults
        RUNS_Routine_RAZIndicDiagTNB_Start
          data-read-access:
            10 x access:
              dra_RP_SR_EtatPrincipalSEV_EtatPrincipalSEV: accessed-variable=RP_SR_EtatPrincipalSEV.EtatPrincipalSEV
              dra_PRP_SR_SAV_EtatCNBMemorisePar2c_SAV_EtatCNBMemorisePar2c: accessed-variable=PRP_SR_SAV_EtatCNBMemorisePar2c.SAV_EtatCNBMemorisePar2c
              dra_PRP_SR_SAV_EtatCNBMemorisePar2d_SAV_EtatCNBMemorisePar2d: accessed-variable=PRP_SR_SAV_EtatCNBMemorisePar2d.SAV_EtatCNBMemorisePar2d
              dra_PRP_SR_SAV_EtatCNBMemorisePar2g_SAV_EtatCNBMemorisePar2g: accessed-variable=PRP_SR_SAV_EtatCNBMemorisePar2g.SAV_EtatCNBMemorisePar2g
              dra_PRP_SR_SAV_EtatCNBMemorisePar3d_SAV_EtatCNBMemorisePar3d: accessed-variable=PRP_SR_SAV_EtatCNBMemorisePar3d.SAV_EtatCNBMemorisePar3d
              dra_PRP_SR_SAV_EtatCNBMemorisePar3g_SAV_EtatCNBMemorisePar3g: accessed-variable=PRP_SR_SAV_EtatCNBMemorisePar3g.SAV_EtatCNBMemorisePar3g
              dra_PRP_SR_SAV_EtatCNBMemorisePavC_SAV_EtatCNBMemorisePavC: accessed-variable=PRP_SR_SAV_EtatCNBMemorisePavC.SAV_EtatCNBMemorisePavC
              dra_PRP_SR_SAV_EtatCNBMemorisePavd_SAV_EtatCNBMemorisePavd: accessed-variable=PRP_SR_SAV_EtatCNBMemorisePavd.SAV_EtatCNBMemorisePavd
              dra_PRP_SR_SAV_EtatCNBMemorisePavg_SAV_EtatCNBMemorisePavg: accessed-variable=PRP_SR_SAV_EtatCNBMemorisePavg.SAV_EtatCNBMemorisePavg
              dra_PRP_SR_SAV_EtatPresenceMemorisePav_SAV_EtatPresenceMemorisePav: accessed-variable=PRP_SR_SAV_EtatPresenceMemorisePav.SAV_EtatPresenceMemorisePav
          data-write-access:
            9 x access:
              dwa_PRP_SR_SAV_EtatCNBMemorisePar2c_SAV_EtatCNBMemorisePar2c: accessed-variable=PRP_SR_SAV_EtatCNBMemorisePar2c.SAV_EtatCNBMemorisePar2c
              dwa_PRP_SR_SAV_EtatCNBMemorisePar2d_SAV_EtatCNBMemorisePar2d: accessed-variable=PRP_SR_SAV_EtatCNBMemorisePar2d.SAV_EtatCNBMemorisePar2d
              dwa_PRP_SR_SAV_EtatCNBMemorisePar2g_SAV_EtatCNBMemorisePar2g: accessed-variable=PRP_SR_SAV_EtatCNBMemorisePar2g.SAV_EtatCNBMemorisePar2g
              dwa_PRP_SR_SAV_EtatCNBMemorisePar3d_SAV_EtatCNBMemorisePar3d: accessed-variable=PRP_SR_SAV_EtatCNBMemorisePar3d.SAV_EtatCNBMemorisePar3d
              dwa_PRP_SR_SAV_EtatCNBMemorisePar3g_SAV_EtatCNBMemorisePar3g: accessed-variable=PRP_SR_SAV_EtatCNBMemorisePar3g.SAV_EtatCNBMemorisePar3g
              dwa_PRP_SR_SAV_EtatCNBMemorisePavC_SAV_EtatCNBMemorisePavC: accessed-variable=PRP_SR_SAV_EtatCNBMemorisePavC.SAV_EtatCNBMemorisePavC
              dwa_PRP_SR_SAV_EtatCNBMemorisePavd_SAV_EtatCNBMemorisePavd: accessed-variable=PRP_SR_SAV_EtatCNBMemorisePavd.SAV_EtatCNBMemorisePavd
              dwa_PRP_SR_SAV_EtatCNBMemorisePavg_SAV_EtatCNBMemorisePavg: accessed-variable=PRP_SR_SAV_EtatCNBMemorisePavg.SAV_EtatCNBMemorisePavg
              dwa_PRP_SR_SAV_EtatPresenceMemorisePav_SAV_EtatPresenceMemorisePav: accessed-variable=PRP_SR_SAV_EtatPresenceMemorisePav.SAV_EtatPresenceMemorisePav
        RUNS_Routine_RAZIndicDiagTNB_Stop
package /RootP_Implementatation
  swc implementation Implementatation_ASWC_A7C: programming-language=C, sw-version=1.0.0, vendor-id=1, behavior=IB_ASWC_A7C
    code-descriptors:
      code SRC: artifact-descriptors=autosar-engineering-object={short-label=EngObject, category=SWSRC}
    resource consumption Resources
